AUTOSAR XML (schema 00050)
package /FCADT/ComponentTypes
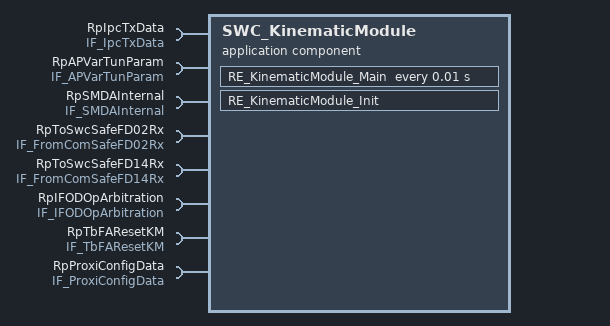
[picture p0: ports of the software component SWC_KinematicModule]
  application sw component type SWC_KinematicModule
    8 x require port:
      RpIpcTxData: client-com-spec=IPC_Write_v, required-interface=IF_IpcTxData
      RpAPVarTunParam: nonqueued-receiver-com-spec{data-element=TbAP_VrntTunParam_t, filter=data-filter-type=ALWAYS}, required-interface=IF_APVarTunParam
      RpSMDAInternal: nonqueued-receiver-com-spec=data-element=TbAP_SMDAInternalOut_t, required-interface=IF_SMDAInternal
      RpToSwcSafeFD02Rx: required-interface=IF_FromComSafeFD02Rx
        required-com-specs:
          data-element=Active_Park_Mode, filter=data-filter-type=ALWAYS, init-value=0
          data-element=Active_Park_Prox_Chime, filter=data-filter-type=ALWAYS, init-value=0
          data-element=APARequestSts, filter=data-filter-type=ALWAYS, init-value=0
          data-element=Backup_Cam_Delay, filter=data-filter-type=ALWAYS, init-value=0
          data-element=Brk_Stat, filter=data-filter-type=ALWAYS, init-value=0
          data-element=CmdIgnSts, filter=data-filter-type=ALWAYS, init-value=0
          data-element=DriverDoorSts, filter=data-filter-type=ALWAYS, init-value=0
          data-element=DynamicGrid, filter=data-filter-type=ALWAYS, init-value=1
          data-element=ExternalTemperature, filter=data-filter-type=ALWAYS, init-value=0
          data-element=FT_PAMRequestSts, filter=data-filter-type=ALWAYS, init-value=0
          data-element=Fwrd_Cam_Guidelines, filter=data-filter-type=ALWAYS, init-value=0
          data-element=GearEngaged, filter=data-filter-type=ALWAYS, init-value=0
          data-element=HAS_Status_C2, filter=data-filter-type=ALWAYS, init-value=0
          data-element=LanguageSelection, filter=data-filter-type=ALWAYS, init-value=0
          data-element=LatAcceleration_BSM, filter=data-filter-type=ALWAYS, init-value=4095
          data-element=LHRDoorSts, filter=data-filter-type=ALWAYS, init-value=0
          data-element=LongAcceleration_BSM, filter=data-filter-type=ALWAYS, init-value=4095
          data-element=LwsAngle, filter=data-filter-type=ALWAYS, init-value=0
          data-element=LwsAngleType, filter=data-filter-type=ALWAYS, init-value=0
          data-element=LwsSpeed, filter=data-filter-type=ALWAYS, init-value=0
          data-element=MRM_STATUS_C2, filter=data-filter-type=ALWAYS, init-value=0
          data-element=PamChimeVolumeFront, filter=data-filter-type=ALWAYS, init-value=1
          data-element=PamChimeVolumeRear, filter=data-filter-type=ALWAYS, init-value=1
          data-element=PAMRequestSts, filter=data-filter-type=ALWAYS, init-value=0
          data-element=PsngrDoorSts, filter=data-filter-type=ALWAYS, init-value=0
          data-element=Rear_Brk_Asst, filter=data-filter-type=ALWAYS, init-value=0
          data-element=RHatchSts, filter=data-filter-type=ALWAYS, init-value=0
          data-element=RHRDoorSts, filter=data-filter-type=ALWAYS, init-value=0
          data-element=ShiftLeverPosition, filter=data-filter-type=ALWAYS, init-value=0
          data-element=SVC_Guidelines, filter=data-filter-type=ALWAYS, init-value=0
          data-element=TargetGear, filter=data-filter-type=ALWAYS, init-value=15
          data-element=TCASERANGESTATUS, filter=data-filter-type=ALWAYS, init-value=0
          data-element=TGW_CAMERA_DISP_STAT, filter=data-filter-type=ALWAYS, init-value=0
          data-element=TrailerConnectionSts, filter=data-filter-type=ALWAYS, init-value=0
          data-element=TRANS_ADAS_Inhibit, filter=data-filter-type=ALWAYS, init-value=0
          data-element=TransmissionSailingSts, filter=data-filter-type=ALWAYS, init-value=0
          data-element=VehicleSpeedVSOSig, filter=data-filter-type=ALWAYS, init-value=0
          data-element=YawRate_BSM, filter=data-filter-type=ALWAYS, init-value=4095
          data-element=VIN_MSG, filter=data-filter-type=ALWAYS
          data-element=VIN_DATA, filter=data-filter-type=ALWAYS
          data-element=RR_Lvl_Adj, filter=data-filter-type=ALWAYS
          data-element=RR_Lvl, filter=data-filter-type=ALWAYS
          data-element=RL_Lvl_Adj, filter=data-filter-type=ALWAYS
          data-element=RL_Lvl, filter=data-filter-type=ALWAYS
          data-element=HU_TRSC_EnableBtn_Sts, filter=data-filter-type=ALWAYS
          data-element=GearEngagedForDisplay, filter=data-filter-type=ALWAYS
          data-element=FR_Lvl_Adj, filter=data-filter-type=ALWAYS
          data-element=FR_Lvl, filter=data-filter-type=ALWAYS
          data-element=FL_Lvl_Adj, filter=data-filter-type=ALWAYS
          data-element=FL_Lvl, filter=data-filter-type=ALWAYS
          data-element=ESS_ENG_ST_W, filter=data-filter-type=ALWAYS
          data-element=EngineSts_W, filter=data-filter-type=ALWAYS
          data-element=ECM_TRSC_Resp, filter=data-filter-type=ALWAYS
          data-element=ECM_THA_Resp, filter=data-filter-type=ALWAYS
          data-element=ASCM_SysFail, filter=data-filter-type=ALWAYS
          data-element=ASCM_Stat, filter=data-filter-type=ALWAYS
          data-element=PdlPosActual, filter=data-filter-type=ALWAYS
          data-element=THA_SteeringTouchStat, filter=data-filter-type=ALWAYS
          data-element=EPS_THA_SteeringTorqueResp, filter=data-filter-type=ALWAYS
          data-element=EPS_THA_DriverTorqueOverride, filter=data-filter-type=ALWAYS
          data-element=EPS_SteeringTouq_Resp, filter=data-filter-type=ALWAYS
          data-element=EPS_SteeringTouchStat, filter=data-filter-type=ALWAYS
          data-element=ShiftLeverPositionReq, filter=data-filter-type=ALWAYS
          data-element=Shifter_ADAS_Inhibit, filter=data-filter-type=ALWAYS
          data-element=ITBM_TrlrStat, filter=data-filter-type=ALWAYS
          data-element=CM_TCH_Y_COORD, filter=data-filter-type=ALWAYS
          data-element=CM_TCH_X_COORD, filter=data-filter-type=ALWAYS
          data-element=CM_TCH_STAT, filter=data-filter-type=ALWAYS
          data-element=CameraDisplaySts2, filter=data-filter-type=ALWAYS
      RpToSwcSafeFD14Rx: required-interface=IF_FromComSafeFD14Rx
        required-com-specs:
          data-element=FD14_ACC_Systemsts, filter=data-filter-type=ALWAYS, init-value=0
          data-element=FD14_Brk_Stat, filter=data-filter-type=ALWAYS, init-value=0
          data-element=FD14_BrkPdl_Stat, filter=data-filter-type=ALWAYS, init-value=3
          data-element=FD14_BrkTrq, filter=data-filter-type=ALWAYS, init-value=32767
          data-element=FD14_BrkTrq_Driver, filter=data-filter-type=ALWAYS, init-value=32767
          data-element=FD14_BSM_THA_Brk_Resp, filter=data-filter-type=ALWAYS, init-value=0
          data-element=FD14_EPBSts, filter=data-filter-type=ALWAYS, init-value=0
          data-element=FD14_EPS_HandsOnRecognition, filter=data-filter-type=ALWAYS, init-value=0
          data-element=FD14_ESC_TRSC_Brk_Resp, filter=data-filter-type=ALWAYS, init-value=0
          data-element=FD14_ExternalBrkRequestsDisabled, filter=data-filter-type=ALWAYS, init-value=0
          data-element=FD14_HAS_Status, filter=data-filter-type=ALWAYS, init-value=0
          data-element=FD14_LatAcceleration_BSM, filter=data-filter-type=ALWAYS, init-value=4095
          data-element=FD14_LatAccelerationFailSts_BSM, filter=data-filter-type=ALWAYS, init-value=0
          data-element=FD14_LatAccelerationOffset_BSM, filter=data-filter-type=ALWAYS, init-value=255
          data-element=FD14_LHF_FastPulseCounter, filter=data-filter-type=ALWAYS, init-value=0
          data-element=FD14_LHF_Spin, filter=data-filter-type=ALWAYS, init-value=0
          data-element=FD14_LHF_WheelSensorFailSts, filter=data-filter-type=ALWAYS, init-value=0
          data-element=FD14_LHFWheelSpeed, filter=data-filter-type=ALWAYS, init-value=0
          data-element=FD14_LHR_FastPulseCounter, filter=data-filter-type=ALWAYS, init-value=0
          data-element=FD14_LHR_Spin, filter=data-filter-type=ALWAYS, init-value=0
          data-element=FD14_LHR_WheelSensorFailSts, filter=data-filter-type=ALWAYS, init-value=0
          data-element=FD14_LHRWheelSpeed, filter=data-filter-type=ALWAYS, init-value=0
          data-element=FD14_LongAcceleration_BSM, filter=data-filter-type=ALWAYS, init-value=4095
          data-element=FD14_LongAccelerationFailSts_BSM, filter=data-filter-type=ALWAYS, init-value=0
          data-element=FD14_LongAccelerationOffset_BSM, filter=data-filter-type=ALWAYS, init-value=255
          data-element=FD14_LwsAngle, filter=data-filter-type=ALWAYS, init-value=0
          data-element=FD14_LwsAngleType, filter=data-filter-type=ALWAYS, init-value=0
          data-element=FD14_LwsSpeed, filter=data-filter-type=ALWAYS, init-value=0
          data-element=FD14_PAM_Brk_Rq_RspSts, filter=data-filter-type=ALWAYS, init-value=0
          data-element=FD14_ParkingGearShiftReq_BSM, filter=data-filter-type=ALWAYS, init-value=0
          data-element=FD14_ParkingInterventionSts, filter=data-filter-type=ALWAYS, init-value=0
          data-element=FD14_REF_VEH_SPEED, filter=data-filter-type=ALWAYS, init-value=1023
          data-element=FD14_RHF_FastPulseCounter, filter=data-filter-type=ALWAYS, init-value=0
          data-element=FD14_RHF_Spin, filter=data-filter-type=ALWAYS, init-value=0
          data-element=FD14_RHF_WheelSensorFailSts, filter=data-filter-type=ALWAYS, init-value=0
          data-element=FD14_RHFWheelSpeed, filter=data-filter-type=ALWAYS, init-value=0
          data-element=FD14_RHR_FastPulseCounter, filter=data-filter-type=ALWAYS, init-value=0
          data-element=FD14_RHR_Spin, filter=data-filter-type=ALWAYS, init-value=0
          data-element=FD14_RHR_WheelSensorFailSts, filter=data-filter-type=ALWAYS, init-value=0
          data-element=FD14_RHRWheelSpeed, filter=data-filter-type=ALWAYS, init-value=0
          data-element=FD14_Slope, filter=data-filter-type=ALWAYS, init-value=0
          data-element=FD14_SPM_Lat_Ctrl_ResponseSts, filter=data-filter-type=ALWAYS, init-value=0
          data-element=FD14_Steering_Column_Torque, filter=data-filter-type=ALWAYS, init-value=0
          data-element=FD14_VehicleSpeedVSOSig, filter=data-filter-type=ALWAYS, init-value=0
          data-element=FD14_VehicleSpeedVSOSig_B2, filter=data-filter-type=ALWAYS, init-value=0
          data-element=FD14_VehicleStandStillSts, filter=data-filter-type=ALWAYS, init-value=1
          data-element=FD14_YawRate_BSM, filter=data-filter-type=ALWAYS, init-value=4095
          data-element=FD14_YawRateFailSts_BSM, filter=data-filter-type=ALWAYS, init-value=0
          data-element=FD14_ESS_ENG_ST_W, filter=data-filter-type=ALWAYS
          data-element=FD14_EngineSts_W, filter=data-filter-type=ALWAYS
          data-element=FD14_ECM_TRSC_Resp, filter=data-filter-type=ALWAYS
          data-element=FD14_ECM_THA_Resp, filter=data-filter-type=ALWAYS
          data-element=FD14_PdlPosActual, filter=data-filter-type=ALWAYS
          data-element=FD14_THA_SteeringTouchStat, filter=data-filter-type=ALWAYS
          data-element=FD14_EPS_THA_SteeringTorqueResp, filter=data-filter-type=ALWAYS
          data-element=FD14_EPS_THA_DriverTorqueOverride, filter=data-filter-type=ALWAYS
          data-element=FD14_EPS_SteeringTouq_Resp, filter=data-filter-type=ALWAYS
          data-element=FD14_EPS_SteeringTouchStat, filter=data-filter-type=ALWAYS
      RpIFODOpArbitration: nonqueued-receiver-com-spec{data-element=IFOD_Outputs_Arbitration_t, filter=data-filter-type=ALWAYS}, required-interface=IF_IFODOpArbitration
      RpTbFAResetKM: nonqueued-receiver-com-spec{data-element=TbFA_ResetKM_t, filter=data-filter-type=ALWAYS}, required-interface=IF_TbFAResetKM
      RpProxiConfigData: nonqueued-receiver-com-spec{data-element=ProxiData, filter=data-filter-type=ALWAYS}, required-interface=IF_ProxiConfigData
    behavior SWC_KinematicModule_InternalBehavior: data-type-mapping=DataTypeMappings_DEV, handle-termination-and-restart=NO-SUPPORT
      init event InitEvent: start-on-event=RE_KinematicModule_Init
      timing event TMT_RE_KinematicModule_Main: start-on-event=RE_KinematicModule_Main, period=0.01
      runnable RE_KinematicModule_Init  # Periodic Runnable of Satellite
      runnable RE_KinematicModule_Main  # Init Runnable
        data-receive-point-by-arguments:
          11 x access:
            REC_RpAPVarTunParam_TbAP_VrntTunParam_t: accessed-variable=RpAPVarTunParam.TbAP_VrntTunParam_t
            REC_RpSMDAInternal_TbAP_SMDAInternalOut_t: accessed-variable=RpSMDAInternal.TbAP_SMDAInternalOut_t
            REC_RpToSwcSafeFD14Rx_FD14_LHR_FastPulseCounter: accessed-variable=RpToSwcSafeFD14Rx.FD14_LHR_FastPulseCounter
            REC_RpToSwcSafeFD14Rx_FD14_LHRWheelSpeed: accessed-variable=RpToSwcSafeFD14Rx.FD14_LHRWheelSpeed
            REC_RpToSwcSafeFD14Rx_FD14_LwsAngle: accessed-variable=RpToSwcSafeFD14Rx.FD14_LwsAngle
            REC_RpToSwcSafeFD14Rx_FD14_RHR_FastPulseCounter: accessed-variable=RpToSwcSafeFD14Rx.FD14_RHR_FastPulseCounter
            REC_RpToSwcSafeFD14Rx_FD14_RHRWheelSpeed: accessed-variable=RpToSwcSafeFD14Rx.FD14_RHRWheelSpeed
            REC_RpToSwcSafeFD02Rx_GearEngaged: accessed-variable=RpToSwcSafeFD02Rx.GearEngaged
            REC_RpIFODOpArbitration_IFOD_Outputs_Arbitration_t: accessed-variable=RpIFODOpArbitration.IFOD_Outputs_Arbitration_t
            REC_RpTbFAResetKM_TbFA_ResetKM_t: accessed-variable=RpTbFAResetKM.TbFA_ResetKM_t
            REC_RpProxiConfigData_ProxiData: accessed-variable=RpProxiConfigData.ProxiData
        sync call SC_RpIpcTxData_IPC_Write_v: operation=RpIpcTxData.IPC_Write_v
  swc implementation SWC_KinematicModule_Implementation: programming-language=C, vendor-id=0, behavior=SWC_KinematicModule_InternalBehavior
    code-descriptors:
      code Default: artifact-descriptors=autosar-engineering-object=category=SWSRC
